AUTOSAR XML (schema 4-2-1)
package /RootP_BSWC_NvDM_Satellite_CORE1_MonitoringASILB
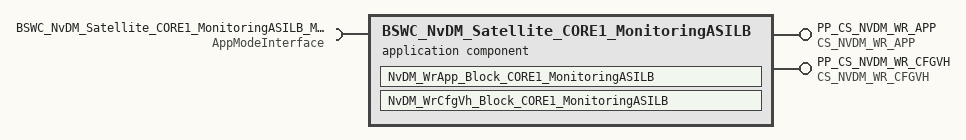
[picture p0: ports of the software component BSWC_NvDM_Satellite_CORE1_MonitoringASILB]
  application sw component type BSWC_NvDM_Satellite_CORE1_MonitoringASILB
    provide port PP_CS_NVDM_WR_APP: server-com-spec{operation=NvDM_WrApp_Block, queue-length=1}, provided-interface=CS_NVDM_WR_APP
    provide port PP_CS_NVDM_WR_CFGVH: server-com-spec{operation=NvDM_WrCfgVh_Block, queue-length=1}, provided-interface=CS_NVDM_WR_CFGVH
    require port BSWC_NvDM_Satellite_CORE1_MonitoringASILB_MSI: required-interface=AppModeInterface
    behavior IB_BSWC_NvDM_Satellite_CORE1_MonitoringASILB: data-type-mapping=ApplicationModeMapping, handle-termination-and-restart=NO-SUPPORT
      operation invoked event PP_CS_NVDM_WR_APP_NvDM_WrApp_Block_OIE: start-on-event=NvDM_WrApp_Block_CORE1_MonitoringASILB, operation=PP_CS_NVDM_WR_APP.NvDM_WrApp_Block
      operation invoked event PP_CS_NVDM_WR_CFGVH_NvDM_WrCfgVh_Block_OIE: start-on-event=NvDM_WrCfgVh_Block_CORE1_MonitoringASILB, operation=PP_CS_NVDM_WR_CFGVH.NvDM_WrCfgVh_Block
      runnable NvDM_WrApp_Block_CORE1_MonitoringASILB: can-be-invoked-concurrently=true
      runnable NvDM_WrCfgVh_Block_CORE1_MonitoringASILB: can-be-invoked-concurrently=true
package /RootP_Implementation
  swc implementation Implementatation_BSWC_NvDM_Satellite_CORE1_MonitoringASILB: programming-language=C, sw-version=1.0.0, vendor-id=1, behavior=IB_BSWC_NvDM_Satellite_CORE1_MonitoringASILB
    code-descriptors:
      code SRC: artifact-descriptors=autosar-engineering-object={short-label=EngObject, category=SWSRC}
    resource consumption Resources
      memory section CODE: sw-addrmethod=CODE_BSWC_NvDM_Satellite_CORE1_MonitoringASILB
  sw addr method CODE_BSWC_NvDM_Satellite_CORE1_MonitoringASILB: memory-allocation-keyword-policy=ADDR-METHOD-SHORT-NAME-AND-ALIGNMENT, section-type=CODE
